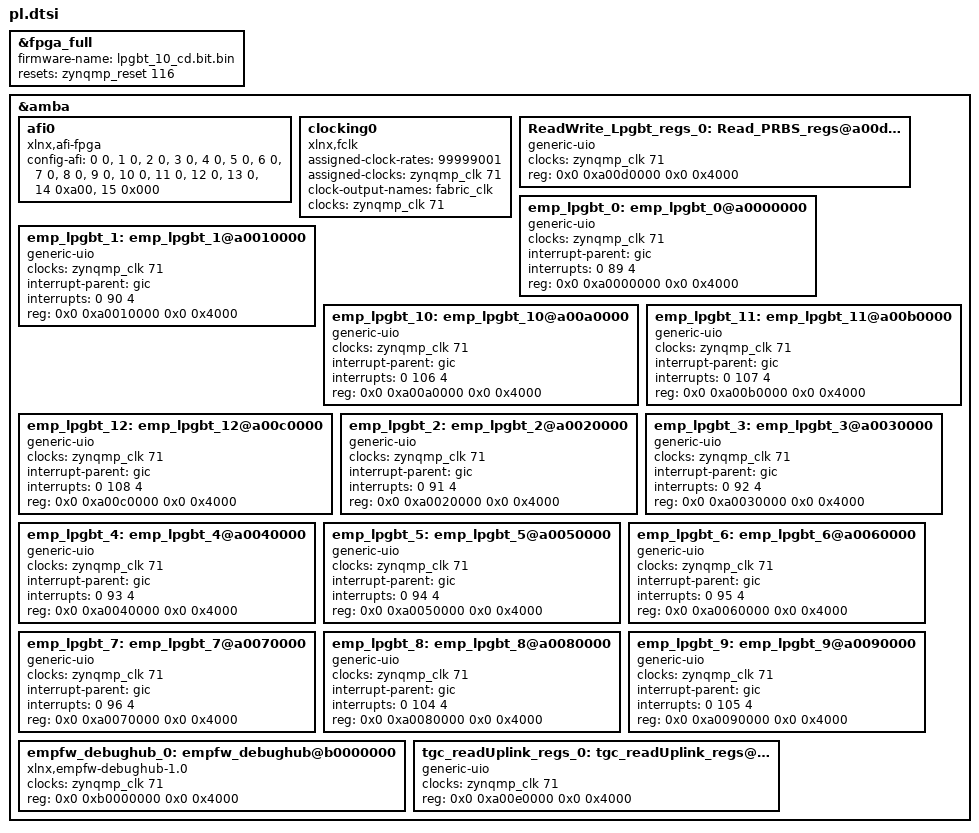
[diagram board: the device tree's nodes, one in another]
/*
 * CAUTION: This file is automatically generated by Xilinx.
 * Version: XSCT 2023.2
 * Today is: Mon Oct 20 18:23:26 2025
 */


/dts-v1/;
/plugin/;
&fpga_full {
			firmware-name = "lpgbt_10_cd.bit.bin";
	resets = <&zynqmp_reset 116>;
};
&amba {
	#address-cells = <2>;
	#size-cells = <2>;
	afi0: afi0 {
		compatible = "xlnx,afi-fpga";
		config-afi = < 0 0>, <1 0>, <2 0>, <3 0>, <4 0>, <5 0>, <6 0>, <7 0>, <8 0>, <9 0>, <10 0>, <11 0>, <12 0>, <13 0>, <14 0xa00>, <15 0x000>;
	};
	clocking0: clocking0 {
		#clock-cells = <0>;
		assigned-clock-rates = <99999001>;
		assigned-clocks = <&zynqmp_clk 71>;
		clock-output-names = "fabric_clk";
		clocks = <&zynqmp_clk 71>;
		compatible = "xlnx,fclk";
	};
	ReadWrite_Lpgbt_regs_0: Read_PRBS_regs@a00d0000 {
		/* This is a place holder node for a custom IP, user may need to update the entries */
		clock-names = "axi_aclk";
		clocks = <&zynqmp_clk 71>;
		compatible = "generic-uio";
		reg = <0x0 0xa00d0000 0x0 0x4000>;
	};
	emp_lpgbt_0: emp_lpgbt_0@a0000000 {
		/* This is a place holder node for a custom IP, user may need to update the entries */
		clock-names = "axi_aclk";
		clocks = <&zynqmp_clk 71>;
		compatible = "generic-uio";
		interrupt-names = "int_lpgbt_resp";
		interrupt-parent = <&gic>;
		interrupts = <0 89 4>;
		reg = <0x0 0xa0000000 0x0 0x4000>;
	};
	emp_lpgbt_1: emp_lpgbt_1@a0010000 {
		/* This is a place holder node for a custom IP, user may need to update the entries */
		clock-names = "axi_aclk";
		clocks = <&zynqmp_clk 71>;
		compatible = "generic-uio";
		interrupt-names = "int_lpgbt_resp";
		interrupt-parent = <&gic>;
		interrupts = <0 90 4>;
		reg = <0x0 0xa0010000 0x0 0x4000>;
	};
	emp_lpgbt_10: emp_lpgbt_10@a00a0000 {
		/* This is a place holder node for a custom IP, user may need to update the entries */
		clock-names = "axi_aclk";
		clocks = <&zynqmp_clk 71>;
		compatible = "generic-uio";
		interrupt-names = "int_lpgbt_resp";
		interrupt-parent = <&gic>;
		interrupts = <0 106 4>;
		reg = <0x0 0xa00a0000 0x0 0x4000>;
	};
	emp_lpgbt_11: emp_lpgbt_11@a00b0000 {
		/* This is a place holder node for a custom IP, user may need to update the entries */
		clock-names = "axi_aclk";
		clocks = <&zynqmp_clk 71>;
		compatible = "generic-uio";
		interrupt-names = "int_lpgbt_resp";
		interrupt-parent = <&gic>;
		interrupts = <0 107 4>;
		reg = <0x0 0xa00b0000 0x0 0x4000>;
	};
	emp_lpgbt_12: emp_lpgbt_12@a00c0000 {
		/* This is a place holder node for a custom IP, user may need to update the entries */
		clock-names = "axi_aclk";
		clocks = <&zynqmp_clk 71>;
		compatible = "generic-uio";
		interrupt-names = "int_lpgbt_resp";
		interrupt-parent = <&gic>;
		interrupts = <0 108 4>;
		reg = <0x0 0xa00c0000 0x0 0x4000>;
	};
	emp_lpgbt_2: emp_lpgbt_2@a0020000 {
		/* This is a place holder node for a custom IP, user may need to update the entries */
		clock-names = "axi_aclk";
		clocks = <&zynqmp_clk 71>;
		compatible = "generic-uio";
		interrupt-names = "int_lpgbt_resp";
		interrupt-parent = <&gic>;
		interrupts = <0 91 4>;
		reg = <0x0 0xa0020000 0x0 0x4000>;
	};
	emp_lpgbt_3: emp_lpgbt_3@a0030000 {
		/* This is a place holder node for a custom IP, user may need to update the entries */
		clock-names = "axi_aclk";
		clocks = <&zynqmp_clk 71>;
		compatible = "generic-uio";
		interrupt-names = "int_lpgbt_resp";
		interrupt-parent = <&gic>;
		interrupts = <0 92 4>;
		reg = <0x0 0xa0030000 0x0 0x4000>;
	};
	emp_lpgbt_4: emp_lpgbt_4@a0040000 {
		/* This is a place holder node for a custom IP, user may need to update the entries */
		clock-names = "axi_aclk";
		clocks = <&zynqmp_clk 71>;
		compatible = "generic-uio";
		interrupt-names = "int_lpgbt_resp";
		interrupt-parent = <&gic>;
		interrupts = <0 93 4>;
		reg = <0x0 0xa0040000 0x0 0x4000>;
	};
	emp_lpgbt_5: emp_lpgbt_5@a0050000 {
		/* This is a place holder node for a custom IP, user may need to update the entries */
		clock-names = "axi_aclk";
		clocks = <&zynqmp_clk 71>;
		compatible = "generic-uio";
		interrupt-names = "int_lpgbt_resp";
		interrupt-parent = <&gic>;
		interrupts = <0 94 4>;
		reg = <0x0 0xa0050000 0x0 0x4000>;
	};
	emp_lpgbt_6: emp_lpgbt_6@a0060000 {
		/* This is a place holder node for a custom IP, user may need to update the entries */
		clock-names = "axi_aclk";
		clocks = <&zynqmp_clk 71>;
		compatible = "generic-uio";
		interrupt-names = "int_lpgbt_resp";
		interrupt-parent = <&gic>;
		interrupts = <0 95 4>;
		reg = <0x0 0xa0060000 0x0 0x4000>;
	};
	emp_lpgbt_7: emp_lpgbt_7@a0070000 {
		/* This is a place holder node for a custom IP, user may need to update the entries */
		clock-names = "axi_aclk";
		clocks = <&zynqmp_clk 71>;
		compatible = "generic-uio";
		interrupt-names = "int_lpgbt_resp";
		interrupt-parent = <&gic>;
		interrupts = <0 96 4>;
		reg = <0x0 0xa0070000 0x0 0x4000>;
	};
	emp_lpgbt_8: emp_lpgbt_8@a0080000 {
		/* This is a place holder node for a custom IP, user may need to update the entries */
		clock-names = "axi_aclk";
		clocks = <&zynqmp_clk 71>;
		compatible = "generic-uio";
		interrupt-names = "int_lpgbt_resp";
		interrupt-parent = <&gic>;
		interrupts = <0 104 4>;
		reg = <0x0 0xa0080000 0x0 0x4000>;
	};
	emp_lpgbt_9: emp_lpgbt_9@a0090000 {
		/* This is a place holder node for a custom IP, user may need to update the entries */
		clock-names = "axi_aclk";
		clocks = <&zynqmp_clk 71>;
		compatible = "generic-uio";
		interrupt-names = "int_lpgbt_resp";
		interrupt-parent = <&gic>;
		interrupts = <0 105 4>;
		reg = <0x0 0xa0090000 0x0 0x4000>;
	};
	empfw_debughub_0: empfw_debughub@b0000000 {
		/* This is a place holder node for a custom IP, user may need to update the entries */
		clock-names = "axi_aclk";
		clocks = <&zynqmp_clk 71>;
		compatible = "xlnx,empfw-debughub-1.0";
		reg = <0x0 0xb0000000 0x0 0x4000>;
	};
	tgc_readUplink_regs_0: tgc_readUplink_regs@a00e0000 {
		/* This is a place holder node for a custom IP, user may need to update the entries */
		clock-names = "axi_aclk";
		clocks = <&zynqmp_clk 71>;
		compatible = "generic-uio";
		reg = <0x0 0xa00e0000 0x0 0x4000>;
	};
};
